# STM32U3B5 register map
File version: 1.0
CPU: CM33 r0p1, little endian, MPU, FPU, 4 interrupt priority bits
Registers are 32-bit, read-write, reset 0x0 unless marked. A register's access mark holds for its fields unless they carry their own. Offsets are from the block's base; [hi:lo] are bit positions; lines under a group give offsets from that group; {n}, {i} and the like mark numbered series; 'fields as' and 'values as' point back to an identical list.

## HSP — HSP register block
Base 0x4002C000
Same registers: SEC_HSP 0x5002C000
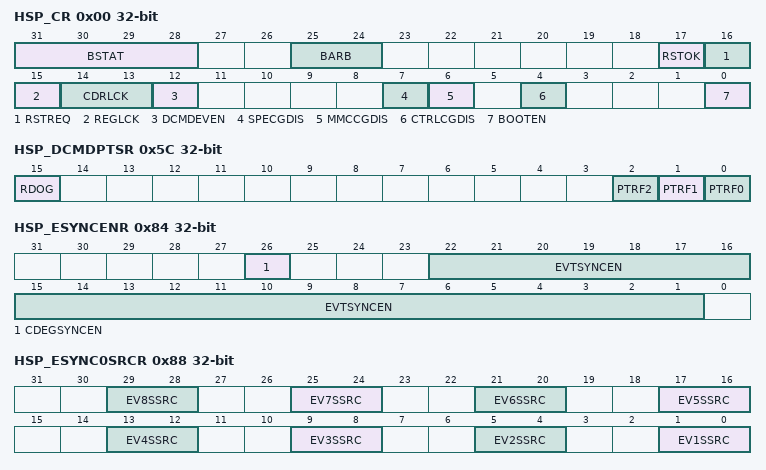
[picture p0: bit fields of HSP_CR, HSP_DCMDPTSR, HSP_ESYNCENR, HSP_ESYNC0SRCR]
0x00 HSP_CR — HSP control register
  [31:28] BSTAT ro — Boot status
    0=Initial value; 2=Start of firmware application
  [25:24] BARB — BRAM arbitration
    0=Max arbitration latency is 16 cycles; 1=Max arbitration latency is 8 cycles; 2=Max arbitration latency is 4 cycles
  [17] RSTOK ro — Reset request accepted
    0=The HSP is not yet set into a state which ensures a safe reset; 1=The HSP can be safely reset
  [16] RSTREQ — Reset request
    0=No HSP reset requested (default after reset); 1=HSP reset requested
  [15] REGLCK — Register write lock access control
    0=Registers are accessible by the CPU through the slave AHB interface (default after reset); 1=Selected registers are write-protected and the CPU cannot change the content
  [14:13] CDRLCK — CRAM and DRAM lock access control
    0=CRAM and DRAM are accessible for read and write operations (default after reset); 1=CRAM and DRAM are write protected, but can be read
  [12] DCMDEVEN — Direct command event enable
    0=Event generation disabled (default after reset); 1=Event generation enabled
  [7] SPECGDIS — SPE clock gating disable
    0=SPE clock gating enabled: SPE clocks are locally gated (default after reset); 1=SPE clock gating disabled: SPE clocks are not locally gated
  [6] MMCCGDIS — MMC clock gating disable
    0=MMC clock gating enabled: MMC clocks are locally gated (default after reset); 1=MMC clock gating disabled: MMC clocks are not locally gated
  [4] CTRLCGDIS — HSP_CTRL clock gating disable
    0=HSP_CTRL clock gating enabled: HSP_CTRL clocks are locally gated (default after reset); 1=HSP_CTRL clock gating disabled: HSP_CTRL clocks are not locally gated
  [0] BOOTEN — Boot enable control
    0=The HSP is not allowed to boot (default after reset); 1=The HSP is allowed to boot, and the SPE executes the code located in the CRAM
0x40 HSP_C2HSEMR — HSP CPU-to-HSP semaphore register
  [0] C2HSEM — CPU to HSP semaphore
    0=The CPU to HSP MSGB is ready to send a new message (default after reset); 1=The CPU to HSP MSGB contains a message for the HSP not yet read
0x44 HSP_C2HMSGDR — HSP CPU-to-HSP message data register
  [31:0] C2HDATA — CPU message for the HSP
0x48 HSP_H2CSEMR — HSP HSP-to-CPU semaphore register
  [0] H2CSEM — HSP to CPU semaphore
    0=The HSP to CPU MSGB does not contain a new message from the HSP (default after reset); 1=The HSP to CPU MSGB contains a new message from the HSP
0x4C HSP_H2CMSGDR ro — HSP HSP-to-CPU message data register
  [31:0] H2CDATA — HSP message for the CPU
0x58 HSP_DCMDSR ro — HSP DCMD command status register
  [0] DCBSY — Direct command busy flag
    0=The current direct command execution is completed; 1=The current direct command execution is ongoing
0x5C HSP_DCMDPTSR ro — HSP DCMD pointer status register
  [15] RDOG — Read ongoing indicator
    0=SPE does not read a pointer (default after reset); 1=SPE is reading a pointer
  [2] PTRF2 — Address pointer 2 flag
    0=SPE read the address pointer 2; 1=The current address pointer 2 has not been read by the SPE
  [1] PTRF1 — Address pointer 1 flag
    0=SPE read the address pointer 1; 1=The current address pointer 1 has not been read by the SPE
  [0] PTRF0 — Address pointer 0 flag
    0=SPE read the address pointer 0; 1=The current address pointer 0 has not been read by the SPE
0x60 HSP_DCMDIDR — HSP DCMD command ID register
  [15:0] CMDID — Command ID
{0x64+4i} HSP_DCMDPTR{i} (i=0..2) — HSP DCMD address pointer register {i}
  [31:0] PTCPU — Address pointer value
0x80 HSP_EVTENR — HSP event enable register
  [22:1] EVTEN — Events enable
    values as HSP_CR.DCMDEVEN
0x84 HSP_ESYNCENR — HSP event synchronization enable register
  [26] CDEGSYNCEN — CPU dedicated event synchronization enable
    0=Synchronization disabled (default after reset); 1=Synchronization enabled
  [22:1] EVTSYNCEN — Event synchronization enable
    values as CDEGSYNCEN
0x88 HSP_ESYNC0SRCR — HSP event synchronization source register 0
  [all] fields
    {v}=tsk_cmp[{v}] selected as synchronization source (v=0..3)
  [4n-3:4n-4] EV{n}SSRC (n=1..8) — Event {n} synchronization source
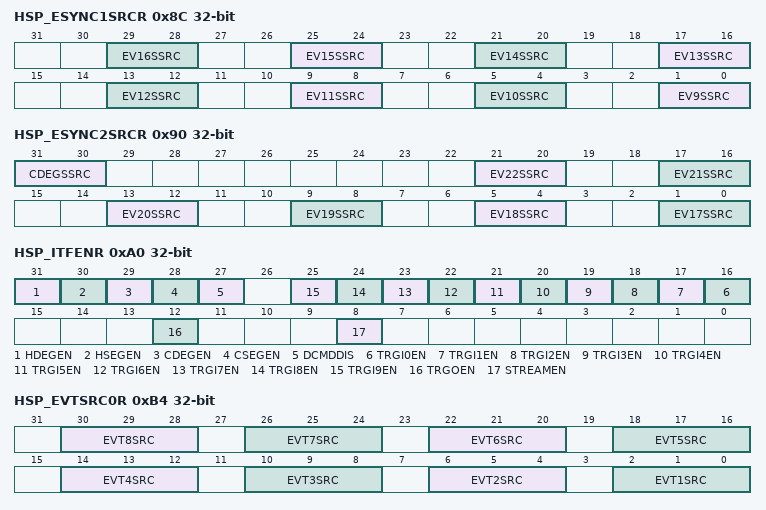
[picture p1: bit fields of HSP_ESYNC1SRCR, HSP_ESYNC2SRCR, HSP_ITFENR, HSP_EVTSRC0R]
0x8C HSP_ESYNC1SRCR — HSP event synchronization source register 1
  [all] fields
    {v}=tsk_cmp[{v}] selected as synchronization source (v=0..3)
  [4n-35:4n-36] EV{n}SSRC (n=9..16) — Event {n} synchronization source
0x90 HSP_ESYNC2SRCR — HSP event synchronization source register 2
  [all] fields
    {v}=tsk_cmp[{v}] selected as synchronization source (v=0..3)
  [31:30] CDEGSSRC — CPU dedicated event synchronization source
  [4n-67:4n-68] EV{n}SSRC (n=17..22) — Event {n} synchronization source
0x98 HSP_PEVTLR ro — HSP pending event level register
  [27:0] EVTL — Event level
    0=Level low (inactive); 1=Level high (pending)
0xA0 HSP_ITFENR rw-once — HSP interface enable register
  [31] HDEGEN ro — HDEG interface enable bit
    0=HDEG interface disabled, and maintained in reset; 1=HDEG interface enabled
  [30] HSEGEN ro — HSEG interface enable bit
    0=HSEG interface disabled, and maintained in reset; 1=HSEG interface enabled
  [29] CDEGEN rw — CDEG interface enable bit
    0=CDEG interface disabled, and maintained in reset; 1=CDEG interface enabled
  [28] CSEGEN rw — CSEG interface enable bit
    0=CSEG interface disabled, and maintained in reset; 1=CSEG interface is enabled
  [27] DCMDDIS — Direct command interface disable bit
    0=Writing this bit to 0 enables the DCMD interface, and prevents other applications to disable it (default after reset); 1=Writing this bit to 1 disables the DCMD interface
  [n+16] TRGI{n}EN rw (n=0..9) — TRGINx enable bit
    0=TRGINx disabled, all the TRGIN logic maintained in reset; 1=TRGINx enabled
  [12] TRGOEN rw — TRGO enable bit
    0=TRGO function disabled, all TRGO outputs (hsp_trgo and hsp_gpo) forced to 0; 1=TRGO function enabled
  [8] STREAMEN rw — STREAM enable
    0=STREAM disabled; 1=STREAM enabled
0xB4 HSP_EVTSRC0R — HSP event source register 0
  [30:28] EVT8SRC — Event source selection for priority encoder input 8
    2=Event provided by the BUFF3 is selected (buff_evt[3]); 3=Event provided by the TRGIN0 is selected (trgin_evt[0]); 4=Event provided by the TRGIN5 is selected (trgin_evt[5]); 5=Event provided by the HSEG is selected (hseg_evt[8]); 6=Event provided by the CSEG is selected (cseg_evt[8])
  [26:24] EVT7SRC — Event source selection for priority encoder input 7
    2=Event provided by the BUFF2 is selected (buff_evt[2]); 3=Event provided by the TRGIN4 is selected (trgin_evt[4]); 4=Event provided by the TRGIN9 is selected (trgin_evt[9]); 5=Event provided by the HSEG is selected (hseg_evt[7]); 6=Event provided by the CSEG is selected (cseg_evt[7])
  [22:20] EVT6SRC — Event source selection for priority encoder input 6
    2=Event provided by the BUFF1 is selected (buff_evt[1]); 3=Event provided by the TRGIN3 is selected (trgin_evt[3]); 4=Event provided by the TRGIN8 is selected (trgin_evt[8]); 5=Event provided by the HSEG is selected (hseg_evt[6]); 6=Event provided by the CSEG is selected (cseg_evt[6])
  [18:16] EVT5SRC — Event source selection for priority encoder input 5
    2=Event provided by the BUFF0 is selected (buff_evt[0]); 3=Event provided by the TRGIN2 is selected (trgin_evt[2]); 4=Event provided by the TRGIN7 is selected (trgin_evt[7]); 5=Event provided by the HSEG is selected (hseg_evt[5]); 6=Event provided by the CSEG is selected (cseg_evt[5])
  [14:12] EVT4SRC — Event source selection for priority encoder input 4
    2=Event provided by the BUFF3 is selected (buff_evt[3]); 3=Event provided by the TRGIN1 is selected (trgin_evt[1]); 4=Event provided by the TRGIN6 is selected (trgin_evt[6]); 5=Event provided by the HSEG is selected (hseg_evt[4]); 6=Event provided by the CSEG is selected (cseg_evt[4])
  [10:8] EVT3SRC — Event source selection for priority encoder input 3
    2=Event provided by the BUFF2 is selected (buff_evt[2]); 3=Event provided by the TRGIN0 is selected (trgin_evt[0]); 4=Event provided by the TRGIN5 is selected (trgin_evt[5]); 5=Event provided by the HSEG is selected (hseg_evt[3]); 6=Event provided by the CSEG is selected (cseg_evt[3])
  [6:4] EVT2SRC — Event source selection for priority encoder input 2
    2=Event provided by the BUFF1 is selected (buff_evt[1]); 3=Event provided by the TRGIN4 is selected (trgin_evt[4]); 4=Event provided by the TRGIN9 is selected (trgin_evt[9]); 5=Event provided by the HSEG is selected (hseg_evt[2]); 6=Event provided by the CSEG is selected (cseg_evt[2])
  [2:0] EVT1SRC — Event source selection for priority encoder input 1
    2=Event provided by the BUFF0 is selected (buff_evt[0]); 3=Event provided by the TRGIN3 is selected (trgin_evt[3]); 4=Event provided by the TRGIN8 is selected (trgin_evt[8]); 5=Event provided by the HSEG is selected (hseg_evt[1]); 6=Event provided by the CSEG is selected (cseg_evt[1])
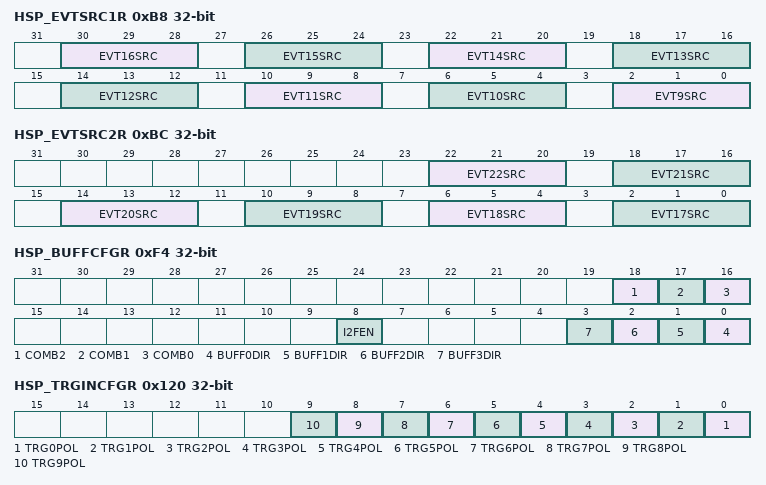
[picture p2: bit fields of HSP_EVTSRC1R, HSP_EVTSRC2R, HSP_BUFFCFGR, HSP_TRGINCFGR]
0xB8 HSP_EVTSRC1R — HSP event source register 1
  [30:28] EVT16SRC — Event source selection for priority encoder input 16
    2=Event provided by the BUFF3 is selected (buff_evt[3]); 3=Event provided by the TRGIN3 is selected (trgin_evt[3]); 4=Event provided by the TRGIN8 is selected (trgin_evt[8]); 5=Event provided by the HSEG is selected (hseg_evt[16]); 6=Event provided by the CSEG is selected (cseg_evt[16])
  [26:24] EVT15SRC — Event source selection for priority encoder input 15
    2=Event provided by the BUFF2 is selected (buff_evt[2]); 3=Event provided by the TRGIN2 is selected (trgin_evt[2]); 4=Event provided by the TRGIN7 is selected (trgin_evt[7]); 5=Event provided by the HSEG is selected (hseg_evt[15]); 6=Event provided by the CSEG is selected (cseg_evt[15])
  [22:20] EVT14SRC — Event source selection for priority encoder input 14
    2=Event provided by the BUFF1 is selected (buff_evt[1]); 3=Event provided by the TRGIN1 is selected (trgin_evt[1]); 4=Event provided by the TRGIN7 is selected (trgin_evt[6]); 5=Event provided by the HSEG is selected (hseg_evt[14]); 6=Event provided by the CSEG is selected (cseg_evt[14])
  [18:16] EVT13SRC — Event source selection for priority encoder input 13
    2=Event provided by the BUFF0 is selected (buff_evt[0]); 3=Event provided by the TRGIN0 is selected (trgin_evt[0]); 4=Event provided by the TRGIN5 is selected (trgin_evt[5]); 5=Event provided by the HSEG is selected (hseg_evt[13]); 6=Event provided by the CSEG is selected (cseg_evt[13])
  [4n-34:4n-36] EVT{n}SRC (n=9..12) — Event source selection for priority encoder input {n}
    2=Event provided by the BUFF{n-9} is selected (buff_evt[{n-9}]); 3=Event provided by the TRGIN{n-8} is selected (trgin_evt[{n-8}]); 4=Event provided by the TRGIN{n-3} is selected (trgin_evt[{n-3}]); 5=Event provided by the HSEG is selected (hseg_evt[{n}]); 6=Event provided by the CSEG is selected (cseg_evt[{n}])
0xBC HSP_EVTSRC2R — HSP event source register 2
  [22:20] EVT22SRC — Event source selection for priority encoder input 22
    2=Event provided by the BUFF1 is selected (buff_evt[1]); 3=Event provided by the TRGIN4 is selected (trgin_evt[4]); 4=Event provided by the TRGIN9 is selected (trgin_evt[9]); 5=Event provided by the HSEG is selected (hseg_evt[22]); 6=Event provided by the CSEG is selected (cseg_evt[22])
  [18:16] EVT21SRC — Event source selection for priority encoder input 21
    2=Event provided by the BUFF0 is selected (buff_evt[0]); 3=Event provided by the TRGIN3 is selected (trgin_evt[3]); 4=Event provided by the TRGIN8 is selected (trgin_evt[8]); 5=Event provided by the HSEG is selected (hseg_evt[21]); 6=Event provided by the CSEG is selected (cseg_evt[21])
  [14:12] EVT20SRC — Event source selection for priority encoder input 20
    2=Event provided by the BUFF3 is selected (buff_evt[3]); 3=Event provided by the TRGIN2 is selected (trgin_evt[2]); 4=Event provided by the TRGIN7 is selected (trgin_evt[7]); 5=Event provided by the HSEG is selected (hseg_evt[20]); 6=Event provided by the CSEG is selected (cseg_evt[20])
  [10:8] EVT19SRC — Event source selection for priority encoder input 19
    2=Event provided by the BUFF2 is selected (buff_evt[2]); 3=Event provided by the TRGIN1 is selected (trgin_evt[1]); 4=Event provided by the TRGIN6 is selected (trgin_evt[6]); 5=Event provided by the HSEG is selected (hseg_evt[19]); 6=Event provided by the CSEG is selected (cseg_evt[19])
  [6:4] EVT18SRC — Event source selection for priority encoder input 18
    2=Event provided by the BUFF1 is selected (buff_evt[1]); 3=Event provided by the TRGIN0 is selected (trgin_evt[0]); 4=Event provided by the TRGIN5 is selected (trgin_evt[5]); 5=Event provided by the HSEG is selected (hseg_evt[18]); 6=Event provided by the CSEG is selected (cseg_evt[18])
  [2:0] EVT17SRC — Event source selection for priority encoder input 17
    2=Event provided by the BUFF0 is selected (buff_evt[0]); 3=Event provided by the TRGIN4 is selected (trgin_evt[4]); 4=Event provided by the TRGIN9 is selected (trgin_evt[9]); 5=Event provided by the HSEG is selected (hseg_evt[17]); 6=Event provided by the CSEG is selected (cseg_evt[17])
0xF4 HSP_BUFFCFGR — HSP BUFF configuration register
  [18] COMB2 — BUFCMB control for buff_evt[x]
    0=buff_evt[x] activated when buff_att[x] is activated; 1=buff_evt[x] activated when buff_att[x] and buff_evt[x+1] are activated
  [17] COMB1 — BUFCMB control for buff_evt[x]
    values as COMB2
  [16] COMB0 — BUFCMB control for buff_evt[x]
    values as COMB2
  [8] I2FEN — Integer to float32 conversion
    0=Integer to float32 conversion disabled; 1=Integer to float32 conversion enabled
  [n] BUFF{n}DIR (n=0..3) — Direction selection of BUFFx
    0=BUFFx direction is C2H (means written by the CPU and read by the HSP); 1=BUFFx direction is H2C (means read by the CPU and written by the HSP)
{0xF8+4i} HSP_BUFF{i}DR (i=0..3) — HSP BUFF{i} data register {i}
  [31:0] BUFFDAT — Data buffer
0x120 HSP_TRGINCFGR — HSP TRGIN configuration register
  [all] fields
    0=TRGINx triggers on rising edge of the input signal; 1=TRGINx triggers on falling edge of the input signal
  [n] TRG{n}POL (n=0..9) — Polarity selection for TRGINx
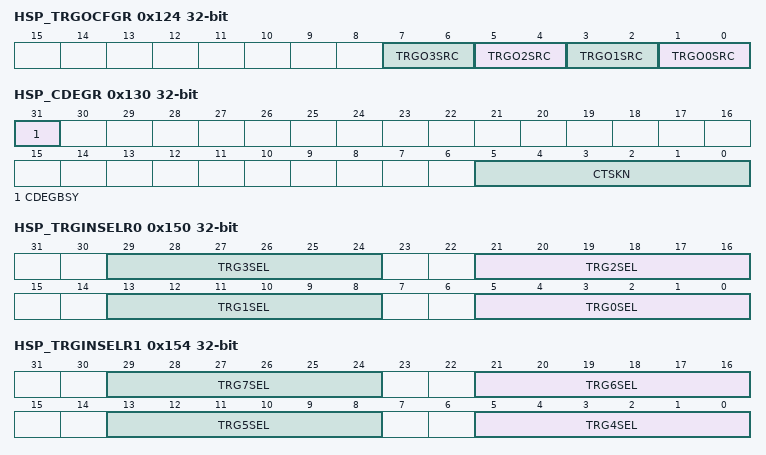
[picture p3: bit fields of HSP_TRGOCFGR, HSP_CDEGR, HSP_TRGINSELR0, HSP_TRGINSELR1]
0x124 HSP_TRGOCFGR — HSP TRGO configuration register
  [all] fields
    0=hsp_trgo[x] disabled; 1=buff_trgo[x] selected as trigger source; 2=spe_trgo[x] selected as trigger source; 3=tsc_trgo selected as trigger source
  [2n+1:2n] TRGO{n}SRC (n=0..3) — Trigger source selection for hsp_trgo[x]
0x12C HSP_CSEGR — HSP CPU shared event generator register
  [22:1] CSEVT — CPU shared software event
    0=Writing 0 has no effect; 1=Writing 1 activates the corresponding event
0x130 HSP_CDEGR — HSP CPU dedicated event generation register
  [31] CDEGBSY ro — CPU dedicated event generator busy
    0=The CDEG ready; 1=The CDEG busy: previous event still under processing
  [5:0] CTSKN — CPU task number
0x150 HSP_TRGINSELR0 — HSP TRGIN input selection register 0
  [all] fields
    0=hsp_trgi[0] input signal selected; 1=hsp_trgi[1] input signal selected
  [8n+5:8n] TRG{n}SEL (n=0..3) — Input trigger selection for TRGIN{n}
0x154 HSP_TRGINSELR1 — HSP TRGIN input selection register 1
  [all] fields
    values as the fields of HSP_TRGINSELR0
  [8n-27:8n-32] TRG{n}SEL (n=4..7) — Input trigger selection for TRGIN{n}
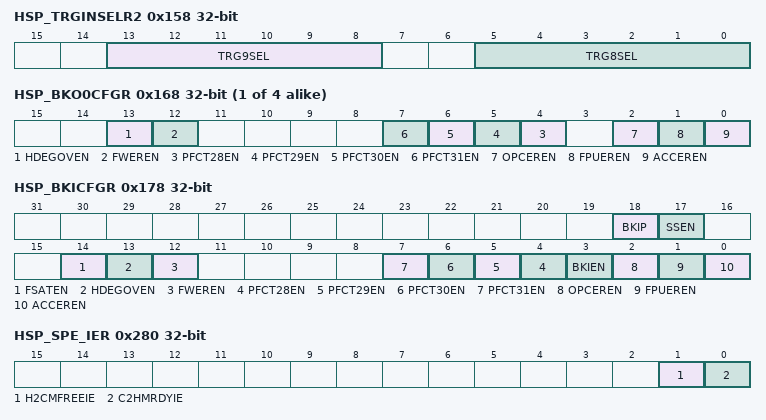
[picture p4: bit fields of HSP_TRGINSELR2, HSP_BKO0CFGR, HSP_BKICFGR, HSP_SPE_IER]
0x158 HSP_TRGINSELR2 — HSP TRGIN input selection register 2
  [13:8] TRG9SEL — Input trigger selection for TRGIN9
    values as the fields of HSP_TRGINSELR0
  [5:0] TRG8SEL — Input trigger selection for TRGIN8
    values as the fields of HSP_TRGINSELR0
{0x168+4i} HSP_BKO{i}CFGR (i=0..3) — HSP break output configuration register {i}
  [13] HDEGOVEN — HSP dedicated event generator overrun break enable for HDEGOVRF
    0=HDEGOVRF flag does not generate a break; 1=HDEGOVRF flag generates a break when asserted
  [12] FWEREN — Firmware error break enable for FWERRF
    0=FWERRF flag does not generate a break; 1=FWERRF flag generates a break when asserted
  [n-24] PFCT{n}EN (n=28..31) — Processing function flag break enable for PFCTF[x]
    0=PFCTF[x] does not generate a break; 1=PFCTF[x] generates a break when asserted
  [2] OPCEREN — Opcode error break enable for OPCOERRF
    0=OPCOERRF flag does not generate a break; 1=OPCOERRF flag generates a break when asserted
  [1] FPUEREN — FPU error break enable for FPUERRF
    0=FPUERRF flag does not generate a break; 1=FPUERRF flag generates a break when asserted
  [0] ACCEREN — Access error break enable for ACCERRF
    0=ACCERRF flag does not generate a break; 1=ACCERRF flag generates a break when asserted
0x178 HSP_BKICFGR — HSP break input configuration register
  [18] BKIP — Break enable input polarity
    0=A break event is generated on hsp_break_in rising edge (if BKEN = 1); 1=A break event is generated on hsp_break_in falling edge (if BKEN = 1)
  [17] SSEN — Single step enable
    0=The single step function is disabled: the SPE is not frozen when the processing function transition detector provides a trigger; 1=The single step function is enabled: the SPE is frozen every time the processing function transition detector provides a trigger
  [14] FSATEN — FPU saturation break enable for FPUSATF
    0=FPUSATF flag does not generate a break; 1=FPUSATF flag generates a break when asserted
  [13] HDEGOVEN — HSP dedicated event generator overrun break enable for HDEGOVRF
    values as HSP_BKO0CFGR.HDEGOVEN
  [12] FWEREN — Firmware error break enable for FWERRF
    values as HSP_BKO0CFGR.FWEREN
  [n-24] PFCT{n}EN (n=28..31) — Processing function flag break enable for PFCTF[x]
    values as HSP_BKO0CFGR.PFCT28EN
  [3] BKIEN — Break enable for hsp_break_in signal
    0=hsp_break_in signal does not generate a break; 1=hsp_break_in signal generates a break when asserted
  [2] OPCEREN — Opcode error break enable for OPCOERRF
    values as HSP_BKO0CFGR.OPCEREN
  [1] FPUEREN — FPU error break enable for FPUERRF
    values as HSP_BKO0CFGR.FPUEREN
  [0] ACCEREN — Access error break enable for ACCERRF
    values as HSP_BKO0CFGR.ACCEREN
0x188 HSP_FWERR ro — HSP firmware error register
  [9:0] FWERRN — Firmware error number
{0x194+4i} HSP_PARAMR{i} reset not defined (i=0..15) — HSP parameter register {i}
  [31:0] PARAM — Parameter value
0x280 HSP_SPE_IER ro — HSP SPE interrupt enable register
  [1] H2CMFREEIE — SPE to CPU message free interrupt enable
    0=Interrupt disabled; 1=Interrupt enabled
  [0] C2HMRDYIE — CPU to SPE message ready interrupt enable
    0=Interrupt disabled; 1=Interrupt enabled
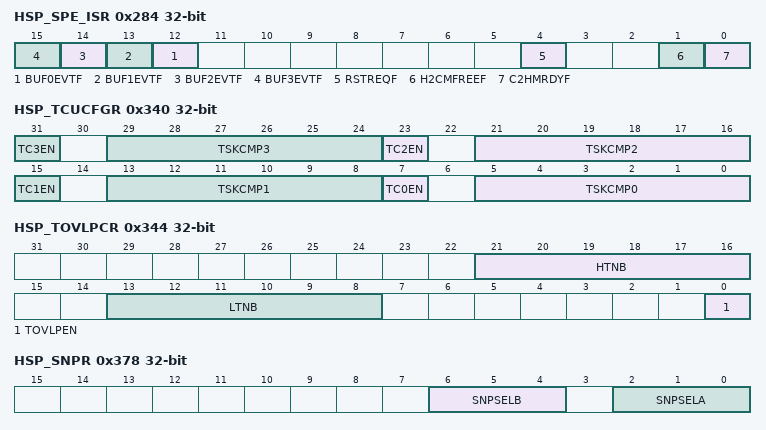
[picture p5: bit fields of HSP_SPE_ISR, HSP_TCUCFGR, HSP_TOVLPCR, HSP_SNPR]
0x284 HSP_SPE_ISR ro — HSP SPE interrupt status register
  [n+12] BUF{n}EVTF (n=0..3) — BUFFx status
    0=No event pending; 1=An event is pending BUFFx empty (if set to C2H) or BUFFx not empty (if set to C2H)
  [4] RSTREQF — HSP reset request
    0=No pending reset request; 1=A reset request from the application is pending
  [1] H2CMFREEF — SPE to CPU message box status
    0=The SPE to CPU message box is not free; 1=The SPE to CPU message box is free
  [0] C2HMRDYF — CPU to SPE message box status
    0=No message from the CPU; 1=A new message from the CPU is available
0x340 HSP_TCUCFGR — HSP task comparator unit register
  [8n+7] TC{n}EN (n=0..3) — Task comparator {n} enable
    0=TSKCMP{n} output disabled; 1=TSKCMP{n} output enabled
  [8n+5:8n] TSKCMP{n} (n=0..3) — Task compare {n}
0x344 HSP_TOVLPCR — HSP task overlap control register
  [21:16] HTNB — Higher task number value
  [13:8] LTNB — Lower task number value
  [0] TOVLPEN — Task overlap enable
    0=Task overlap detector disabled; 1=Task overlap detector enabled
0x378 HSP_SNPR — HSP SNOOP register
  [6:4] SNPSELB — SNOOP group B signal selection
    0=HSP_SNP[5:3] outputs are disabled; {v}=Selects signal set {v} to HSP_SNP[5:3] outputs (v=1..7)
  [2:0] SNPSELA — SNOOP group A signal selection
    0=HSP_SNP[2:0] outputs are disabled; {v}=Selects signal set {v} to HSP_SNP[2:0] outputs (v=1..7)
0x37C HSP_CCNTR ro — HSP conflict counter register
  [31:0] CCNTR — Conflict counter
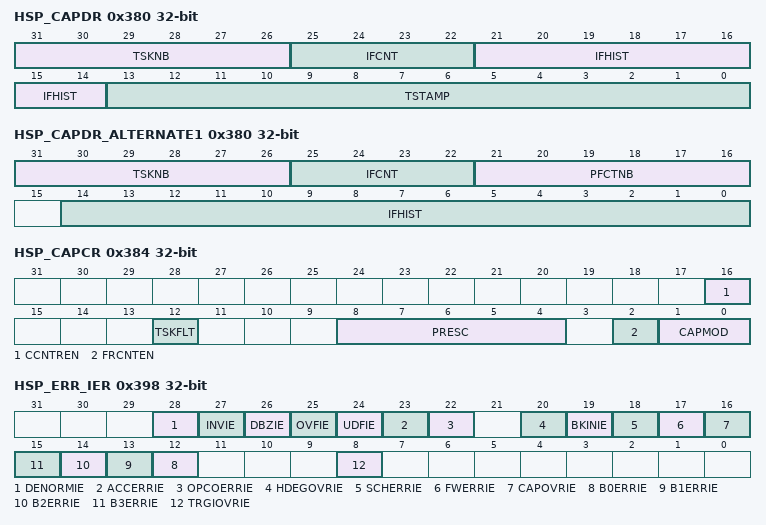
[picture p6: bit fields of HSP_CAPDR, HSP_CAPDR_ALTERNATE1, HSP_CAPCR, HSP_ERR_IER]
0x380 HSP_CAPDR ro — HSP data capture register
  [31:26] TSKNB — Last captured task number
  [25:22] IFCNT — IF instruction counter
  [21:14] IFHIST — IF condition history
  [13:0] TSTAMP — Time-stamp value
0x380 HSP_CAPDR_ALTERNATE1 ro (alternate view of HSP_CAPDR) — HSP data capture register
  [31:26] TSKNB — Last captured task number
  [25:22] IFCNT — IF instruction counter
  [21:16] PFCTNB — Last captured processing function number
  [14:0] IFHIST — IF condition history
0x384 HSP_CAPCR — HSP capture control register
  [16] CCNTREN — Conflict counter enable
    0=Conflict counter disabled, and reset to 0; 1=Conflict counter enabled
  [12] TSKFLT — Task filter enable
    0=The trace controller asserts the tsc_pfcttd signal every time the processing function is executed, independently to the task number running; 1=The trace controller asserts the tsc_pfcttd signal every time the processing function executed when the task selected by TSKCMP0[5:0] is running
  [8:4] PRESC — Time-stamp prescaler value
    0=Clock division is 1 (bypassed); 1=Clock division is hsp_xclk_core_ck / 2; 2=Clock division is hsp_xclk_core_ck / 4; 3=Clock division is hsp_xclk_core_ck / 8; 4=Clock division is hsp_xclk_core_ck / 16; 5=Clock division is hsp_xclk_core_ck / 32; 6=Clock division is hsp_xclk_core_ck / 64; 7=Clock division is hsp_xclk_core_ck / 128; 8=Clock division is hsp_xclk_core_ck / 256; 9=Clock division is hsp_xclk_core_ck / 512; 10=Clock division is hsp_xclk_core_ck / 1024; 11=Clock division is hsp_xclk_core_ck / 2048; 12=Clock division is hsp_xclk_core_ck / 4096; 13=Clock division is hsp_xclk_core_ck / 8192; 14=Clock division is hsp_xclk_core_ck / 16384; 15=Clock division is hsp_xclk_core_ck / 32768
  [2] FRCNTEN — Free-running counter enable
    0=The free-running counter and prescaler are disabled and reset; 1=The free-running counter and prescaler are enabled
  [1:0] CAPMOD — Capture mode
    0=Capture function is disabled; 1=A capture is performed every time the SPE breaks; 2=A capture is performed every time the task number changes; 3=A capture is performed every time the processing function number changes
0x398 HSP_ERR_IER — HSP error interrupt enable register
  [28] DENORMIE — FPU denormal interrupt enable
    0=Denormal exception does not activate the FPUERRF flag; 1=Denormal exception activates the FPUERRF flag
  [27] INVIE — FPU Invalid exception interrupt enable
    0=Invalid exception does not activate the FPUERRF flag; 1=Invalid exception activates the FPUERRF flag
  [26] DBZIE — FPU division-by-zero exception interrupt enable
    0=Division-by-zero exception does not activate the FPUERRF flag; 1=Division-by-zero exception activates the FPUERRF flag
  [25] OVFIE — FPU overflow exception interrupt enable
    0=Overflow exception does not activate the FPUERRF flag; 1=Overflow exception activates the FPUERRF flag
  [24] UDFIE — FPU underflow exception interrupt enable
    0=Underflow exception does not activate the FPUERRF flag; 1=Underflow exception activates the FPUERRF flag
  [23] ACCERRIE — SPE access error interrupt enable
    0=Access error interrupt disabled; 1=Access error interrupt enabled
  [22] OPCOERRIE — Invalid OpCode error interrupt enable
    0=OpCode error interrupt disabled; 1=OpCode error interrupt enabled
  [20] HDEGOVRIE — SPE event overrun interrupt enable
    0=SPE event overrun interrupt disabled; 1=SPE event overrun interrupt enabled
  [19] BKINIE — Break input interrupt enable
    0=Break input interrupt disabled; 1=Break input interrupt enabled
  [18] SCHERRIE — Scheduler error interrupt enable
    0=Scheduler error interrupt disabled; 1=Scheduler error interrupt enabled
  [17] FWERRIE — Firmware error interrupt enable
    0=Firmware error interrupt disabled; 1=Firmware error interrupt enabled
  [16] CAPOVRIE — Capture register overrun interrupt enable
    0=Capture register overrun interrupt disabled; 1=Capture register overrun interrupt enabled
  [n+12] B{n}ERRIE (n=0..3) — H2CBUFFx underrun or C2HBUFFx overrun interrupt enable
    0=H2C/C2HBUFFx underrun/overrun interrupt disabled; 1=H2C/C2HBUFFx underrun/overrun interrupt enabled
  [8] TRGIOVRIE — TRGITF overrun interrupt enable
    0=TRGITF overrun interrupt disabled; 1=TRGITF overrun interrupt enabled
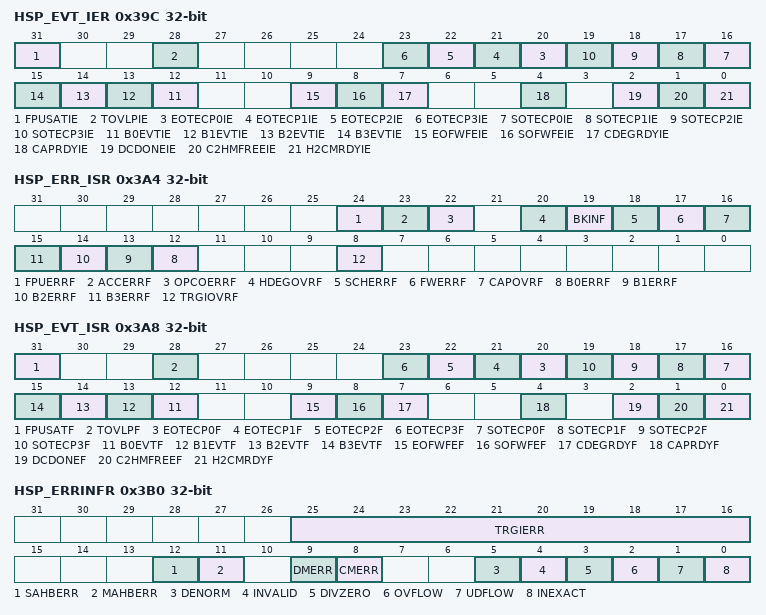
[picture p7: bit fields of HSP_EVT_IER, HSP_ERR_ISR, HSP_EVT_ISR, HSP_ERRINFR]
0x39C HSP_EVT_IER — HSP events interrupt enable register
  [31] FPUSATIE — Saturation flag interrupt enable
    0=Saturation interrupt disabled; 1=Saturation interrupt enabled
  [28] TOVLPIE — Task overlap flag interrupt enable
    0=Task overlap interrupt disabled; 1=Task overlap interrupt enabled
  [n+20] EOTECP{n}IE (n=0..3) — End of task generated by event comparator x interrupt enable
    0=End of task interrupt generated by event comparator x disabled; 1=End of task interrupt generated by event comparator x enabled
  [n+16] SOTECP{n}IE (n=0..3) — Start of task generated by event comparator x interrupt enable
    0=Start of task interrupt generated by event comparator x disabled; 1=Start of task interrupt generated by event comparator x enabled
  [n+12] B{n}EVTIE (n=0..3) — BUFFx event interrupt enable
    0=BUFFx event interrupt disabled; 1=BUFFx event interrupt enabled
  [9] EOFWFEIE — End of WFE interrupt enable
    0=End of WFE interrupt disabled; 1=End of WFE interrupt enabled
  [8] SOFWFEIE — Start of WFE interrupt enable
    0=Start of WFE interrupt disabled; 1=Start of WFE interrupt enabled
  [7] CDEGRDYIE — CPU dedicated event generator ready interrupt enable
    0=Dedicated software event generator ready interrupt disabled; 1=Dedicated software event generator ready interrupt enabled
  [4] CAPRDYIE — Capture buffer data ready interrupt enable
    0=Capture buffer data ready interrupt disabled; 1=Capture buffer data ready interrupt enabled
  [2] DCDONEIE — Direct command done interrupt enable
    0=End of direct command execution interrupt disabled; 1=End of direct command execution interrupt enabled
  [1] C2HMFREEIE — CPU to HSP message box free interrupt enable
    0=CPU to HSP message free interrupt disabled; 1=CPU to HSP message free interrupt enabled
  [0] H2CMRDYIE — HSP to CPU message ready interrupt enable
    0=HSP to CPU message ready interrupt disabled; 1=HSP to CPU message ready interrupt enabled
0x3A0 HSP_PFCTEVT_IER — HSP processing event interrupt enable register
  [31:0] PFCTIE — Processing function flags interrupt enable
    0=Interrupt not generated on flag activation; 1=Interrupt generated on flag activation
0x3A4 HSP_ERR_ISR ro — HSP error interrupt status register
  [24] FPUERRF — Computation error flag
    0=No computation error event detected; 1=A computation error event detected
  [23] ACCERRF — SPE Access error flag
    0=No access error event detected; 1=An access error event detected
  [22] OPCOERRF — Invalid OpCode error flag
    0=No OpCode error event detected; 1=An OpCode error event detected
  [20] HDEGOVRF — SPE event overrun flag
    0=No SPE event overrun event detected; 1=An SPE event overrun event detected
  [19] BKINF — Break input flag
    0=No break input event detected; 1=A break input event detected
  [18] SCHERRF — Scheduler error flag
    0=No scheduler error detected; 1=A scheduler error detected
  [17] FWERRF — Firmware error flag
    0=No firmware error detected; 1=A firmware error detected (see HSP firmware error register (HSP_FWERR) to get the firmware error number)
  [16] CAPOVRF — Capture register overrun flag
    0=No capture register overrun event detected; 1=A capture register overrun event detected
  [n+12] B{n}ERRF (n=0..3) — H2CBUFFx underrun or C2HBUFFx overrun flag
    0=No H2C/C2HBUFFx underrun/overrun event detected; 1=A H2C/C2HBUFFx underrun/overrun event detected
  [8] TRGIOVRF — TRGITF overrun flag
    0=No TRGITF overrun event detected; 1=An TRGITF overrun event detected
0x3A8 HSP_EVT_ISR ro — HSP events interrupt status register
  [31] FPUSATF — FPU saturation flag
    0=No saturation detected; 1=A saturation detected
  [28] TOVLPF — Task overlap flag
    0=No task overlap situation detected; 1=A task overlap situation in the specified task range detected
  [n+20] EOTECP{n}F (n=0..3) — End of task flag, for event comparator x
    0=No end of task event detected; 1=An end of task event detected
  [n+16] SOTECP{n}F (n=0..3) — Start of task flag, for event comparator x
    0=No start of task event detected; 1=A start of task event detected
  [n+12] B{n}EVTF (n=0..3) — BUFFx event flag
    0=BUFFx not empty (if configured in C2H) or BUFFx empty if configured in H2C; 1=BUFFx empty (if configured in C2H) or BUFFx not empty if configured in H2C
  [9] EOFWFEF — End of WFE flag
    0=No end of WFE event detected; 1=End of WFE event is detected
  [8] SOFWFEF — Start of WFE flag
    0=No start of WFE event detected; 1=Start of WFE event detected
  [7] CDEGRDYF — CPU dedicated event generator ready flag
    0=CDEG not ready; 1=CDEG ready to accept the generation of a new event
  [4] CAPRDYF — Capture buffer data ready flag
    0=No capture buffer data ready event detected; 1=A capture buffer data ready event detected
  [2] DCDONEF — Direct command done flag
    0=No direct command under execution, or current execution not yet completed; 1=Direct command execution completed
  [1] C2HMFREEF — CPU to HSP message box free flag
    0=No CPU to HSP message busy event detected; 1=A CPU to HSP message busy event detected
  [0] H2CMRDYF — HSP to CPU message ready flag
    0=No HSP to CPU message ready event detected; 1=A HSP to CPU message ready event detected
0x3AC HSP_PFCTEVT_ISR ro — HSP processing event interrupt status register
  [31:0] PFCTF — Flags generated by SPE processing functions
    0=Flag not active; 1=Flag active
0x3B0 HSP_ERRINFR ro — HSP error information register
  [25:16] TRGIERR — TRGIN error information
  [12] SAHBERR — Slave AHB access error flag
    0=The MMC did not detect invalid accesses from the device; 1=The MMC detected invalid accesses from the device
  [11] MAHBERR — Internal AHB access error flag
    0=The SPE did not generate an AHB access error; 1=The SPE generates an AHB error when accessing to HSP_CTRL
  [9] DMERR — Data memory access error flag
    0=The SPE did not generate a DRAM/BRAM access error; 1=The SPE performed a load/store outside the DRAM/BRAM range
  [8] CMERR — Code memory access error flag
    0=The SPE did not generate a CRAM/CROM access error; 1=The SPE performed a fetch/load outside the CRAM/CROM memory range
  [5] DENORM — Denormal exception flag
    0=No Denormal exception detected; 1=Denormal exception detected
  [4] INVALID — Invalid exception flag
    0=No Invalid exception detected; 1=Invalid exception detected
  [3] DIVZERO — Division by zero exception flag
    0=No division by 0 exception detected; 1=Division by 0 exception detected
  [2] OVFLOW — Overflow exception flag
    0=No Overflow exception detected; 1=Overflow exception detected
  [1] UDFLOW — Underflow exception flag
    0=No Underflow exception detected; 1=Underflow exception detected
  [0] INEXACT — Inexact exception flag
    0=No Inexact exception detected; 1=Inexact exception detected
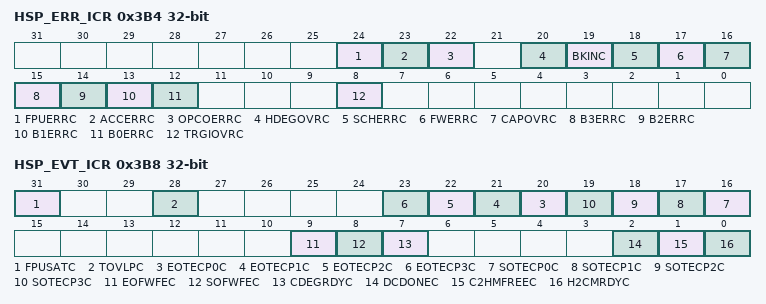
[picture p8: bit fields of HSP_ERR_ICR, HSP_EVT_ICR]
0x3B4 HSP_ERR_ICR wo — HSP error interrupt clear register
  [24] FPUERRC — FPUERRF flag clear
    0=No effect; 1=Clears FPUERRF in HSP_ERR_ISR
  [23] ACCERRC — ACCERRF flag clear
    0=No effect; 1=Clears ACCERRF in HSP_ERR_ISR, and also SAHBERR, MAHBERR, STIERR, DMERR, and CMERR in HSP_ERRINFR
  [22] OPCOERRC — OPCOERRF flag clear
    0=No effect; 1=Clears OPCOERRF in HSP_ERR_ISR
  [20] HDEGOVRC — HDEGOVRF flag clear
    0=No effect; 1=Clears HDEGOVRF in HSP_ERR_ISR
  [19] BKINC — BKINF flag clear
    0=No effect; 1=Clears BKINF in HSP_ERR_ISR
  [18] SCHERRC — SCHERRF flag clear
    0=No effect; 1=Clears SCHERRF in HSP_ERR_ISR
  [17] FWERRC — FWERRF flag clear
    0=No effect; 1=Clears FWERRF in HSP_ERR_ISR
  [16] CAPOVRC — CAPOVRF flag clear
    0=No effect; 1=Clears CAPOVRF in HSP_ERR_ISR
  [15] B3ERRC — B3ERRF flag clear
    0=No effect; 1=Clears B3ERRF in HSP_ERR_ISR
  [14] B2ERRC — B2ERRF flag clear
    0=No effect; 1=Clears B2ERRFin HSP_ERR_ISR
  [13] B1ERRC — B1ERRF flag clear
    0=No effect; 1=Clears B1ERRF in HSP_ERR_ISR
  [12] B0ERRC — B0ERRF flag clear
    0=No effect; 1=Clears B0ERRF in HSP_ERR_ISR
  [8] TRGIOVRC — TRGIOVRF flag clear
    0=No effect; 1=Clears TRGIOVRF in HSP_ERR_ISR
0x3B8 HSP_EVT_ICR wo — HSP events interrupt clear register
  [31] FPUSATC — FPUSATF flag clear
    0=No effect; 1=Clears FPUSATF in HSP_EVT_ISR
  [28] TOVLPC — TOVLPF flag clear
    0=No effect; 1=Clears TOVLPF in HSP_EVT_ISR
  [n+20] EOTECP{n}C (n=0..3) — EOTECPxF flag clear
    0=No effect; 1=Clears EOTECPxF in HSP_EVT_ISR
  [n+16] SOTECP{n}C (n=0..3) — SOTECPxF flag clear
    0=No effect; 1=Clears SOTECP3F in HSP_EVT_ISR
  [9] EOFWFEC — EOFWFEF flag clear
    0=No effect; 1=Clears EOFWFEF in HSP_EVT_ISR
  [8] SOFWFEC — SOFWFEF flag clear
    0=No effect; 1=Clears SOFWFEFF in HSP_EVT_ISR
  [7] CDEGRDYC — CDEGRDYF flag clear
    0=No effect; 1=Clears CDEGRDYF in HSP_EVT_ISR
  [2] DCDONEC — DCDONEF flag clear
    0=No effect; 1=Clears DCDONEF in HSP_EVT_ISR
  [1] C2HMFREEC — C2HMFREEF flag clear
    0=No effect; 1=Clears C2HMFREEF in HSP_EVT_ISR
  [0] H2CMRDYC — H2CMRDYF flag clear
    0=No effect; 1=Clears H2CMRDYF in HSP_EVT_ISR
0x3BC HSP_PFCTEVT_ICR wo — HSP processing event interrupt clear register
  [31:0] PFCTC — PFCTF[31:0] flag clear
    0=No effect; 1=Clears PFCTFn in HSP_PFCTEVT_ISR
